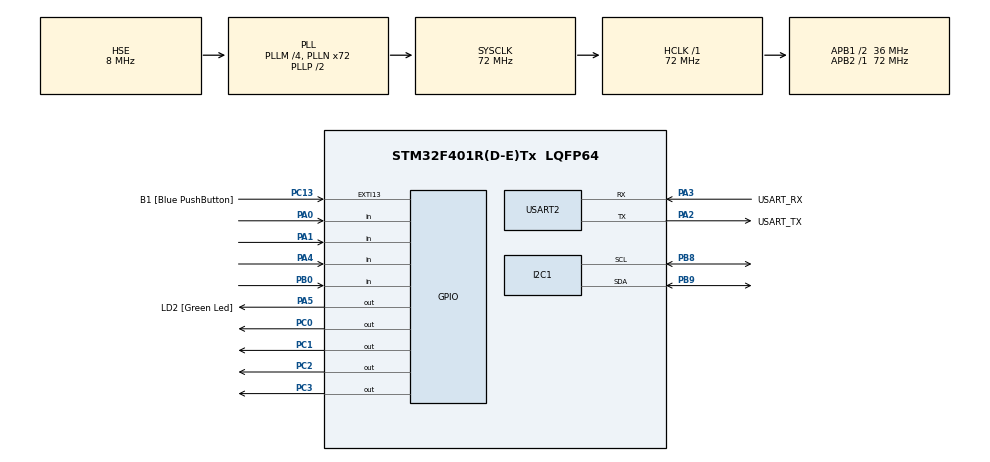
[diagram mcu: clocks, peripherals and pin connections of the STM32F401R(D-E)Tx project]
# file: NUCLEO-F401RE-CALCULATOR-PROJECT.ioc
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Mcu.Family=STM32F4
Mcu.Name=STM32F401R(D-E)Tx
Mcu.Package=LQFP64
NVIC.PriorityGroup=NVIC_PRIORITYGROUP_0
PA0-WKUP.Signal=GPIO_Input
PA1.Signal=GPIO_Input
PA13.GPIO_Label=TMS
PA13.Mode=Serial_Wire
PA13.Signal=SYS_JTMS-SWDIO
PA14.GPIO_Label=TCK
PA14.Mode=Serial_Wire
PA14.Signal=SYS_JTCK-SWCLK
PA2.GPIO_Label=USART_TX
PA2.GPIO_Mode=GPIO_MODE_AF_PP
PA2.GPIO_PuPd=GPIO_NOPULL
PA2.GPIO_Speed=GPIO_SPEED_FREQ_LOW
PA2.Mode=Asynchronous
PA2.Signal=USART2_TX
PA3.GPIO_Label=USART_RX
PA3.GPIO_Mode=GPIO_MODE_AF_PP
PA3.GPIO_PuPd=GPIO_NOPULL
PA3.GPIO_Speed=GPIO_SPEED_FREQ_LOW
PA3.Mode=Asynchronous
PA3.Signal=USART2_RX
PA4.Signal=GPIO_Input
PA5.GPIO_Label=LD2 [Green Led]
PA5.GPIO_Mode=GPIO_MODE_OUTPUT_PP
PA5.GPIO_PuPd=GPIO_NOPULL
PA5.GPIO_Speed=GPIO_SPEED_FREQ_LOW
PA5.Signal=GPIO_Output
PB0.Signal=GPIO_Input
PB3.GPIO_Label=SWO
PB3.Signal=SYS_JTDO-SWO
PB8.Mode=I2C
PB8.Signal=I2C1_SCL
PB9.Mode=I2C
PB9.Signal=I2C1_SDA
PC0.Signal=GPIO_Output
PC1.Signal=GPIO_Output
PC13-ANTI_TAMP.GPIO_Label=B1 [Blue PushButton]
PC13-ANTI_TAMP.GPIO_ModeDefaultEXTI=GPIO_MODE_IT_FALLING
PC13-ANTI_TAMP.GPIO_PuPd=GPIO_NOPULL
PC13-ANTI_TAMP.Signal=GPXTI13
PC14-OSC32_IN.Mode=LSE-External-Oscillator
PC14-OSC32_IN.Signal=RCC_OSC32_IN
PC15-OSC32_OUT.Mode=LSE-External-Oscillator
PC15-OSC32_OUT.Signal=RCC_OSC32_OUT
PC2.Signal=GPIO_Output
PC3.Signal=GPIO_Output
PH0\ -\ OSC_IN.Mode=HSE-External-Oscillator
PH0\ -\ OSC_IN.Signal=RCC_OSC_IN
PH1\ -\ OSC_OUT.Mode=HSE-External-Oscillator
PH1\ -\ OSC_OUT.Signal=RCC_OSC_OUT
ProjectManager.HeapSize=0x200
ProjectManager.StackSize=0x400
ProjectManager.TargetToolchain=STM32CubeIDE
RCC.48MHZClocksFreq_Value=20571428.57142857
RCC.AHBFreq_Value=72000000
RCC.APB1CLKDivider=RCC_HCLK_DIV2
RCC.APB1Freq_Value=36000000
RCC.APB1TimFreq_Value=72000000
RCC.APB2Freq_Value=72000000
RCC.APB2TimFreq_Value=72000000
RCC.CortexFreq_Value=72000000
RCC.HCLKFreq_Value=72000000
RCC.HSE_VALUE=8000000
RCC.HSI_VALUE=16000000
RCC.PLLM=4
RCC.PLLN=72
RCC.PLLQ=7
RCC.PLLSourceVirtual=RCC_PLLSOURCE_HSE
RCC.SYSCLKFreq_VALUE=72000000
RCC.SYSCLKSource=RCC_SYSCLKSOURCE_PLLCLK
RCC.VCOOutputFreq_Value=144000000
USART2.VirtualMode=VM_ASYNC
board=NUCLEO-F401RE

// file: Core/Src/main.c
/* USER CODE BEGIN Header */
/**
  ******************************************************************************
  * @file           : main.c
  * @brief          : Main program body
  ******************************************************************************
  * @attention
  *
  * Copyright (c) 2023 STMicroelectronics.
  * All rights reserved.
  *
  * This software is licensed under terms that can be found in the LICENSE file
  * in the root directory of this software component.
  * If no LICENSE file comes with this software, it is provided AS-IS.
  *
  ******************************************************************************
  */
/* USER CODE END Header */
#include <arithmetic_calculator.h>
#include "main.h"
#include "i2c-lcd.h"
#include "keypad-lib.h"
#include "string.h"
#include <stdio.h>
#include "calc-write-lcd-hundler.h"
#include "alarm-sound.h"

I2C_HandleTypeDef hi2c1;

UART_HandleTypeDef huart2;

void SystemClock_Config(void);
static void MX_GPIO_Init(void);
static void MX_USART2_UART_Init(void);
static void MX_I2C1_Init(void);

int main(void)
{

  /* MCU Configuration--------------------------------------------------------*/

  /* Reset of all peripherals, Initializes the Flash interface and the Systick. */
  HAL_Init();

  /* Configure the system clock */
  SystemClock_Config();

  /* Initialize all configured peripherals */
  MX_GPIO_Init();
  MX_USART2_UART_Init();
  MX_I2C1_Init();
  lcd_init();
  /* USER CODE BEGIN 2 */
  lcd_put_cur(0, 0);
  HAL_Delay(100);
  char str[2] = {'\0'};
  char expression[16*2] = {'\0'};
  char ch;
  char ch_printed = 'x';
  int row, col, exp_index;
  row = col = exp_index = 0 ;
  /* USER CODE END 2 */

  /* Infinite loop */
  while (1)
  {
	  ch = keypad_read();
	  if(ch!= '\0' && ch_printed != ch){
		  alert();
		  if(ch!='#' && ch!='D'){
			  expression[exp_index] = ch;
			  str[0] = ch;
			  lcd_put_cur(row, col);
			  lcd_send_string(str);
			  cursor_deplacement_right(&row, &col);
			  exp_index++;
		  }
		  else if(ch == '#'){
			  lcd_put_cur(row, col);
			  remove_cursor_element(&row, &col);
			  expression[exp_index] = '\0';
			  if (exp_index != 0)
				  exp_index--;
		  }
		  else if(ch == 'D'){
			  calculate_and_display(expression);
		  }

	  }
	  ch_printed = ch;
	  HAL_Delay(200);
  }
}

void SystemClock_Config(void)
{
  RCC_OscInitTypeDef RCC_OscInitStruct = {0};
  RCC_ClkInitTypeDef RCC_ClkInitStruct = {0};

  /** Configure the main internal regulator output voltage
  */
  __HAL_RCC_PWR_CLK_ENABLE();
  __HAL_PWR_VOLTAGESCALING_CONFIG(PWR_REGULATOR_VOLTAGE_SCALE2);

  /** Initializes the RCC Oscillators according to the specified parameters
  * in the RCC_OscInitTypeDef structure.
  */
  RCC_OscInitStruct.OscillatorType = RCC_OSCILLATORTYPE_HSE;
  RCC_OscInitStruct.HSEState = RCC_HSE_ON;
  RCC_OscInitStruct.PLL.PLLState = RCC_PLL_ON;
  RCC_OscInitStruct.PLL.PLLSource = RCC_PLLSOURCE_HSE;
  RCC_OscInitStruct.PLL.PLLM = 4;
  RCC_OscInitStruct.PLL.PLLN = 72;
  RCC_OscInitStruct.PLL.PLLP = RCC_PLLP_DIV2;
  RCC_OscInitStruct.PLL.PLLQ = 7;
  if (HAL_RCC_OscConfig(&RCC_OscInitStruct) != HAL_OK)
  {
    Error_Handler();
  }

  /** Initializes the CPU, AHB and APB buses clocks
  */
  RCC_ClkInitStruct.ClockType = RCC_CLOCKTYPE_HCLK|RCC_CLOCKTYPE_SYSCLK
                              |RCC_CLOCKTYPE_PCLK1|RCC_CLOCKTYPE_PCLK2;
  RCC_ClkInitStruct.SYSCLKSource = RCC_SYSCLKSOURCE_PLLCLK;
  RCC_ClkInitStruct.AHBCLKDivider = RCC_SYSCLK_DIV1;
  RCC_ClkInitStruct.APB1CLKDivider = RCC_HCLK_DIV2;
  RCC_ClkInitStruct.APB2CLKDivider = RCC_HCLK_DIV1;

  if (HAL_RCC_ClockConfig(&RCC_ClkInitStruct, FLASH_LATENCY_2) != HAL_OK)
  {
    Error_Handler();
  }
}

static void MX_I2C1_Init(void)
{

  hi2c1.Instance = I2C1;
  hi2c1.Init.ClockSpeed = 100000;
  hi2c1.Init.DutyCycle = I2C_DUTYCYCLE_2;
  hi2c1.Init.OwnAddress1 = 0;
  hi2c1.Init.AddressingMode = I2C_ADDRESSINGMODE_7BIT;
  hi2c1.Init.DualAddressMode = I2C_DUALADDRESS_DISABLE;
  hi2c1.Init.OwnAddress2 = 0;
  hi2c1.Init.GeneralCallMode = I2C_GENERALCALL_DISABLE;
  hi2c1.Init.NoStretchMode = I2C_NOSTRETCH_DISABLE;
  if (HAL_I2C_Init(&hi2c1) != HAL_OK)
  {
    Error_Handler();
  }

}

static void MX_USART2_UART_Init(void)
{

  huart2.Instance = USART2;
  huart2.Init.BaudRate = 115200;
  huart2.Init.WordLength = UART_WORDLENGTH_8B;
  huart2.Init.StopBits = UART_STOPBITS_1;
  huart2.Init.Parity = UART_PARITY_NONE;
  huart2.Init.Mode = UART_MODE_TX_RX;
  huart2.Init.HwFlowCtl = UART_HWCONTROL_NONE;
  huart2.Init.OverSampling = UART_OVERSAMPLING_16;
  if (HAL_UART_Init(&huart2) != HAL_OK)
  {
    Error_Handler();
  }

}

static void MX_GPIO_Init(void)
{
  GPIO_InitTypeDef GPIO_InitStruct = {0};

  /* GPIO Ports Clock Enable */
  __HAL_RCC_GPIOC_CLK_ENABLE();
  __HAL_RCC_GPIOH_CLK_ENABLE();
  __HAL_RCC_GPIOA_CLK_ENABLE();
  __HAL_RCC_GPIOB_CLK_ENABLE();

  /*Configure GPIO pin Output Level */
  HAL_GPIO_WritePin(GPIOC, GPIO_PIN_0|GPIO_PIN_1|GPIO_PIN_2|GPIO_PIN_3, GPIO_PIN_RESET);

  /*Configure GPIO pin Output Level */
  HAL_GPIO_WritePin(LD2_GPIO_Port, LD2_Pin, GPIO_PIN_RESET);

  /*Configure GPIO pin : B1_Pin */
  GPIO_InitStruct.Pin = B1_Pin;
  GPIO_InitStruct.Mode = GPIO_MODE_IT_FALLING;
  GPIO_InitStruct.Pull = GPIO_PULLDOWN;
  HAL_GPIO_Init(B1_GPIO_Port, &GPIO_InitStruct);

  /*Configure GPIO pins : PC0 PC1 PC2 PC3 */
  GPIO_InitStruct.Pin = GPIO_PIN_0|GPIO_PIN_1|GPIO_PIN_2|GPIO_PIN_3;
  GPIO_InitStruct.Mode = GPIO_MODE_OUTPUT_PP;
  GPIO_InitStruct.Pull = GPIO_PULLDOWN;
  GPIO_InitStruct.Speed = GPIO_SPEED_FREQ_LOW;
  HAL_GPIO_Init(GPIOC, &GPIO_InitStruct);

  /*Configure GPIO pins : PA0 PA1 PA4 */
  GPIO_InitStruct.Pin = GPIO_PIN_0|GPIO_PIN_1|GPIO_PIN_4;
  GPIO_InitStruct.Mode = GPIO_MODE_INPUT;
  GPIO_InitStruct.Pull = GPIO_PULLDOWN;
  HAL_GPIO_Init(GPIOA, &GPIO_InitStruct);

  /*Configure GPIO pin : LD2_Pin */
  GPIO_InitStruct.Pin = LD2_Pin;
  GPIO_InitStruct.Mode = GPIO_MODE_OUTPUT_PP;
  GPIO_InitStruct.Pull = GPIO_PULLDOWN;
  GPIO_InitStruct.Speed = GPIO_SPEED_FREQ_LOW;
  HAL_GPIO_Init(LD2_GPIO_Port, &GPIO_InitStruct);

  /*Configure GPIO pin : PB0 */
  GPIO_InitStruct.Pin = GPIO_PIN_0;
  GPIO_InitStruct.Mode = GPIO_MODE_INPUT;
  GPIO_InitStruct.Pull = GPIO_PULLDOWN;
  HAL_GPIO_Init(GPIOB, &GPIO_InitStruct);

}

void Error_Handler(void)
{
  __disable_irq();
  while (1)
  {
  }
}
